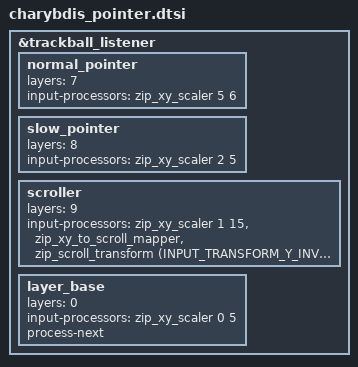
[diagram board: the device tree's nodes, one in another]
#include <input/processors.dtsi>
#include <dt-bindings/zmk/input_transform.h>

&trackball_listener {
    /* base processor chain on all layers */
    /*input-processors = <&zip_xy_scaler 5 5>, <&zip_temp_layer 7 300>;*/
    // input-processors = <&zip_xy_scaler 5 5>;

    /* pointer normal speed */
    normal_pointer: normal_pointer {
        layers           = <7>;
        input-processors = <&zip_xy_scaler 5 6>;
    };

    
    /* slow-pointer override */
    slow_pointer: slow_pointer {
        layers           = <8>;
        input-processors = <&zip_xy_scaler 2 5>;
    };

    /* scroll override */
    scroller: scroller {
        layers           = <9>;
        input-processors = <
            &zip_xy_scaler 1 15                              // Scales the scroll speed
            &zip_xy_to_scroll_mapper                         // Converts XY movement to scroll events
            &zip_scroll_transform (INPUT_TRANSFORM_Y_INVERT) // Inverts the scroll direction
        >;
    };

    layer_base: layer_base {
        layers           = <0>;
        input-processors = <&zip_xy_scaler 0 5>;
        process-next;
    };
};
